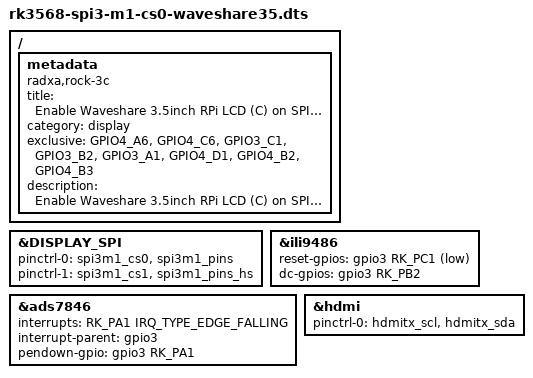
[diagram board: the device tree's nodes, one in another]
#define DISPLAY_SPI spi3
#include "waveshare35-lcd.dtsi"

/ {
	metadata {
		title = "Enable Waveshare 3.5inch RPi LCD (C) on SPI3-M1";
		compatible = "radxa,rock-3c", "radxa,zero3";
		category = "display";
		exclusive = "GPIO4_A6", "GPIO4_C6", "GPIO3_C1", "GPIO3_B2", "GPIO3_A1", "GPIO4_D1", "GPIO4_B2", "GPIO4_B3";
		description = "Enable Waveshare 3.5inch RPi LCD (C) on SPI3-M1.
HDMI CEC function will be turned off when this overlay is enabled.";
	};
};

&DISPLAY_SPI {
	pinctrl-names = "default", "high_speed";
	pinctrl-0 = <&spi3m1_cs0 &spi3m1_pins>;
	pinctrl-1 = <&spi3m1_cs1 &spi3m1_pins_hs>;
};

&ili9486 {
	reset-gpios = <&gpio3 RK_PC1 GPIO_ACTIVE_LOW>;
	dc-gpios = <&gpio3 RK_PB2 GPIO_ACTIVE_HIGH>;
};

&ads7846 {
	interrupts = <RK_PA1 IRQ_TYPE_EDGE_FALLING>;
	interrupt-parent = <&gpio3>;
	pendown-gpio = <&gpio3 RK_PA1 GPIO_ACTIVE_HIGH>;
};

&hdmi {
	pinctrl-names = "default";
	pinctrl-0 = <&hdmitx_scl &hdmitx_sda>; 
};
